# AM13E230x register map
Vendor: Texas Instruments; File version: Revised: 2025-12-26 17:30:06
CPU: CM33 r0p0, little endian, MPU, FPU, 4 interrupt priority bits
Registers are 32-bit, read-write, reset 0x0 unless marked. A register's access mark holds for its fields unless they carry their own. Offsets are from the block's base; [hi:lo] are bit positions; {n}, {i} and the like mark numbered series; 'fields as' and 'values as' point back to an identical list.

## ADC0_RESULT
Base 0x4000A000
Same registers: ADC1_RESULT 0x4000B000, ADC2_RESULT 0x4000C000
{0x0+2i} ADCRESULT{i} 16-bit (i=0..15)
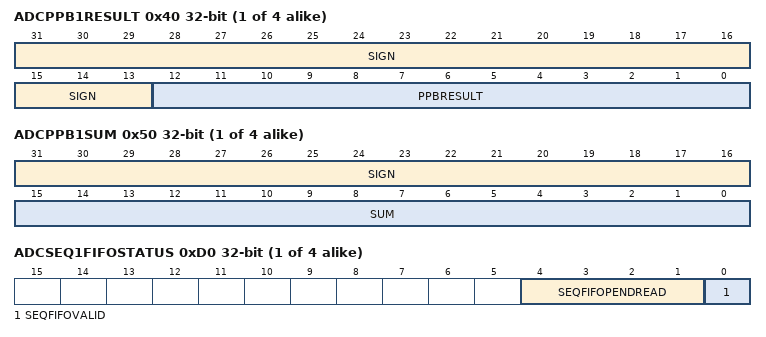
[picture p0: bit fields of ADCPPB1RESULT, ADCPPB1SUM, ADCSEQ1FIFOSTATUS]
{0x3C+4i} ADCPPB{i}RESULT (i=1..4) — ADC Post Processing Block {i} Result Register
  [31:13] SIGN ro — Sign Extended Bits
  [12:0] PPBRESULT ro — ADC Post Processing Block Result
{0x48+8i} ADCPPB{i}SUM (i=1..4) — ADC PPB {i} Final Sum Result Register
  [31:16] SIGN ro — Sign Extended Bits
  [15:0] SUM ro — Post Processing Block {i} Oversampling Sum
{0x4C+8i} ADCPPB{i}COUNT 16-bit (i=1..4) — ADC PPB{i} Final Conversion Count Register
  [3:0] COUNT ro — Post Processing Block {i} Final Count
{0xBC+4i} ADCSEQ{i}FIFORESULT (i=1..4) — ADC Sequence {i} FIFO Result Register
{0xCC+4i} ADCSEQ{i}FIFOSTATUS (i=1..4) — ADC Sequence {i} FIFO Status
  [4:1] SEQFIFOPENDREAD ro — Sequencer {i} FIFO Pending reads
  [0] SEQFIFOVALID ro — Sequencer {i} FIFO Valid

## CMPSS0 — CMPSS_LITE_REGS
Base 0x40460000
Same registers: CMPSS1 0x40461000, CMPSS2 0x40462000, CMPSS3 0x40463000
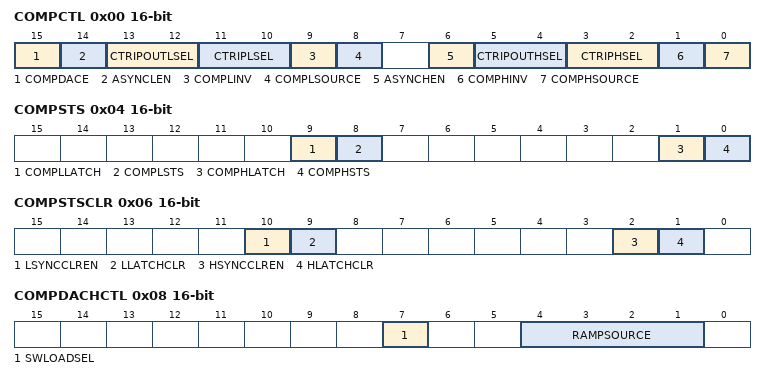
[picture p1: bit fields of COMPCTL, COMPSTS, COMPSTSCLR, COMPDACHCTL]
0x00 COMPCTL 16-bit — CMPSS Comparator Control Register
  [15] COMPDACE — Comparator/DAC Enable
  [14] ASYNCLEN — Low Comparator Asynchronous Path Enable
  [13:12] CTRIPOUTLSEL — Low Comparator Trip Output Select
  [11:10] CTRIPLSEL — Low Comparator Trip Select
  [9] COMPLINV — Low Comparator Invert Select
  [8] COMPLSOURCE — Low Comparator Source Select
  [6] ASYNCHEN — High Comparator Asynchronous Path Enable
  [5:4] CTRIPOUTHSEL — High Comparator Trip Output Select
  [3:2] CTRIPHSEL — High Comparator Trip Select
  [1] COMPHINV — High Comparator Invert Select
  [0] COMPHSOURCE — High Comparator Source Select
0x02 COMPHYSCTL 16-bit — CMPSS Comparator Hysteresis Control Register
  [3:0] COMPHYS — Comparator Hysteresis Trim
0x04 COMPSTS 16-bit — CMPSS Comparator Status Register
  [9] COMPLLATCH ro — Low Comparator Latched Status
  [8] COMPLSTS ro — Low Comparator Status
  [1] COMPHLATCH ro — High Comparator Latched Status
  [0] COMPHSTS ro — High Comparator Status
0x06 COMPSTSCLR 16-bit — CMPSS Comparator Status Clear Register
  [10] LSYNCCLREN — Low Comparator EPWMSYNCPER Clear Enable
  [9] LLATCHCLR — Low Comparator Latched Status Clear
  [2] HSYNCCLREN — High Comparator EPWMSYNCPER Clear Enable
  [1] HLATCHCLR — High Comparator Latched Status Clear
0x08 COMPDACHCTL 16-bit — CMPSS High DAC Control Register
  [7] SWLOADSEL — Software Load Select
  [4:1] RAMPSOURCE — Ramp Generator Source Control
0x0C DACHVALS 16-bit — CMPSS High DAC Value Shadow Register
  [11:0] DACVAL — DAC Value Control
0x0E DACHVALA 16-bit — CMPSS High DAC Value Active Register
  [11:0] DACVAL ro — DAC Value Control
0x24 DACLVALS 16-bit — CMPSS Low DAC Value Shadow Register
  [11:0] DACVAL — DAC Value Control
0x26 DACLVALA 16-bit — CMPSS Low DAC Value Active Register
  [11:0] DACVAL ro — DAC Value Control
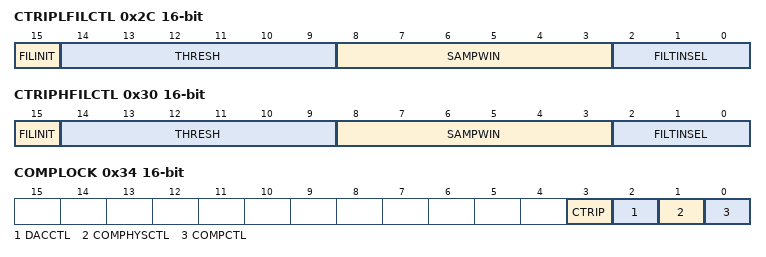
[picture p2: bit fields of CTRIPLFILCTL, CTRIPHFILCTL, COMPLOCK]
0x2C CTRIPLFILCTL 16-bit — CTRIPL Filter Control Register
  [15] FILINIT — Filter Initialization Bit
  [14:9] THRESH — Majority Voting Threshold
  [8:3] SAMPWIN — Sample Window
  [2:0] FILTINSEL — Filter Input Select
0x2E CTRIPLFILCLKCTL 16-bit — CTRIPL Filter Clock Control Register
0x30 CTRIPHFILCTL 16-bit — CTRIPH Filter Control Register
  fields as CTRIPLFILCTL
0x32 CTRIPHFILCLKCTL 16-bit — CTRIPH Filter Clock Control Register
0x34 COMPLOCK 16-bit — CMPSS Lock Register
  [3] CTRIP — CTRIP Lock
  [2] DACCTL — DACCTL Lock
  [1] COMPHYSCTL — COMPHYSCTL Lock
  [0] COMPCTL — COMPCTL Lock
0x48 COMPDACLCTL 16-bit — CMPSS Low DAC Control Register
  [4:1] RAMPSOURCE — Ramp Generator Source Control
0x6E CTRIPLFILCLKCTL2 16-bit — CTRIPL Filter Clock Control Register 2
  [7:0] CLKPRESCALEU — Sample Clock Prescale Upper Bits
0x72 CTRIPHFILCLKCTL2 16-bit — CTRIPH Filter Clock Control Register 2
  [7:0] CLKPRESCALEU — Sample Clock Prescale Upper Bits
